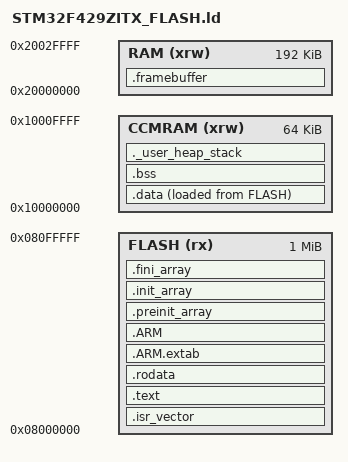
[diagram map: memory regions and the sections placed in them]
/*
******************************************************************************
**
** @file        : LinkerScript.ld
**
** @author      : Auto-generated by STM32CubeIDE
**
**  Abstract    : Linker script for STM32F429I-DISC1 Board embedding STM32F429ZITx Device from stm32f4 series
**                      2048KBytes FLASH
**                      64KBytes CCMRAM
**                      192KBytes RAM
**
**                Set heap size, stack size and stack location according
**                to application requirements.
**
**                Set memory bank area and size if external memory is used
**
**  Target      : STMicroelectronics STM32
**
**  Distribution: The file is distributed as is, without any warranty
**                of any kind.
**
******************************************************************************
** @attention
**
** Copyright (c) 2026 STMicroelectronics.
** All rights reserved.
**
** This software is licensed under terms that can be found in the LICENSE file
** in the root directory of this software component.
** If no LICENSE file comes with this software, it is provided AS-IS.
**
******************************************************************************
*/

/* Entry Point */
ENTRY(Reset_Handler)

/* Memory split, because the framebuffers live in internal SRAM now (no
   SDRAM, see display.c):

     RAM     (192K)  the two 240x320 L8 framebuffers, 150K, in .framebuffer.
                     The LTDC reads them over the bus matrix, so they have
                     to be here: the CCM is wired to the CPU only.
     CCMRAM  (64K)   everything else, .data, .bss, heap and stack. Nothing
                     in this firmware reads memory by DMA, so all of it may
                     sit where only the CPU sees it, and the CPU sees the
                     CCM without wait states.

   The startup code copies .data and clears .bss by the symbols below,
   wherever they are, and the CCM is clocked out of reset. */

/* Highest address of the user mode stack */
_estack = ORIGIN(CCMRAM) + LENGTH(CCMRAM);

_Min_Heap_Size = 0x200; /* required amount of heap */
/* Stack: the deepest user is the AI search with two 220 byte map copies,
   every function is held below 4K by -Wstack-usage in the Makefile. */
_Min_Stack_Size = 0x4000; /* required amount of stack */

/* Memories definition */
/* FLASH is capped at bank 1 (1024K of the 2048K the part has) on
   purpose: bank 2 holds the high score (sectors 14/15, hiscore_flash.c).
   An image that outgrew bank 1 fails at link time instead of being
   erased by a save. */
MEMORY
{
  CCMRAM    (xrw)    : ORIGIN = 0x10000000,   LENGTH = 64K
  RAM    (xrw)    : ORIGIN = 0x20000000,   LENGTH = 192K
  FLASH    (rx)    : ORIGIN = 0x8000000,   LENGTH = 1024K
}

/* Sections */
SECTIONS
{

  /* The startup code into "FLASH" Rom type memory */
  .isr_vector :
  {
    . = ALIGN(4);
    KEEP(*(.isr_vector)) /* Startup code */
    . = ALIGN(4);
  } >FLASH

  /* The program code and other data into "FLASH" Rom type memory */
  .text :
  {
    . = ALIGN(4);
    *(.text)           /* .text sections (code) */
    *(.text*)          /* .text* sections (code) */
    *(.glue_7)         /* glue arm to thumb code */
    *(.glue_7t)        /* glue thumb to arm code */
    *(.eh_frame)

    KEEP (*(.init))
    KEEP (*(.fini))

    . = ALIGN(4);
    _etext = .;        /* define a global symbols at end of code */
  } >FLASH

  /* Constant data into "FLASH" Rom type memory */
  .rodata :
  {
    . = ALIGN(4);
    *(.rodata)         /* .rodata sections (constants, strings, etc.) */
    *(.rodata*)        /* .rodata* sections (constants, strings, etc.) */
    . = ALIGN(4);
  } >FLASH

  .ARM.extab (READONLY) : /* The "READONLY" keyword is only supported in GCC11 and later, remove it if using GCC10 or earlier. */
  {
    . = ALIGN(4);
    *(.ARM.extab* .gnu.linkonce.armextab.*)
    . = ALIGN(4);
  } >FLASH

  .ARM (READONLY) : /* The "READONLY" keyword is only supported in GCC11 and later, remove it if using GCC10 or earlier. */
  {
    . = ALIGN(4);
    __exidx_start = .;
    *(.ARM.exidx*)
    __exidx_end = .;
    . = ALIGN(4);
  } >FLASH

  .preinit_array (READONLY) : /* The "READONLY" keyword is only supported in GCC11 and later, remove it if using GCC10 or earlier. */
  {
    . = ALIGN(4);
    PROVIDE_HIDDEN (__preinit_array_start = .);
    KEEP (*(.preinit_array*))
    PROVIDE_HIDDEN (__preinit_array_end = .);
    . = ALIGN(4);
  } >FLASH

  .init_array (READONLY) : /* The "READONLY" keyword is only supported in GCC11 and later, remove it if using GCC10 or earlier. */
  {
    . = ALIGN(4);
    PROVIDE_HIDDEN (__init_array_start = .);
    KEEP (*(SORT(.init_array.*)))
    KEEP (*(.init_array*))
    PROVIDE_HIDDEN (__init_array_end = .);
    . = ALIGN(4);
  } >FLASH

  .fini_array (READONLY) : /* The "READONLY" keyword is only supported in GCC11 and later, remove it if using GCC10 or earlier. */
  {
    . = ALIGN(4);
    PROVIDE_HIDDEN (__fini_array_start = .);
    KEEP (*(SORT(.fini_array.*)))
    KEEP (*(.fini_array*))
    PROVIDE_HIDDEN (__fini_array_end = .);
    . = ALIGN(4);
  } >FLASH

  /* Used by the startup to initialize data */
  _sidata = LOADADDR(.data);

  /* Initialized data sections into "CCMRAM" */
  .data :
  {
    . = ALIGN(4);
    _sdata = .;        /* create a global symbol at data start */
    *(.data)           /* .data sections */
    *(.data*)          /* .data* sections */
    *(.RamFunc)        /* .RamFunc sections */
    *(.RamFunc*)       /* .RamFunc* sections */

    . = ALIGN(4);
    _edata = .;        /* define a global symbol at data end */

  } >CCMRAM AT> FLASH

  /* Uninitialized data section into "CCMRAM" */
  . = ALIGN(4);
  .bss :
  {
    /* This is used by the startup in order to initialize the .bss section */
    _sbss = .;         /* define a global symbol at bss start */
    __bss_start__ = _sbss;
    *(.bss)
    *(.bss*)
    *(COMMON)

    . = ALIGN(4);
    _ebss = .;         /* define a global symbol at bss end */
    __bss_end__ = _ebss;
  } >CCMRAM

  /* User_heap_stack section, used to check that there is enough CCM left */
  ._user_heap_stack :
  {
    . = ALIGN(8);
    PROVIDE ( end = . );
    PROVIDE ( _end = . );
    . = . + _Min_Heap_Size;
    . = . + _Min_Stack_Size;
    . = ALIGN(8);
  } >CCMRAM

  /* The framebuffers, in SRAM for the LTDC. Not cleared by the startup:
     display_init() fills them before the panel shows anything. */
  .framebuffer (NOLOAD) :
  {
    . = ALIGN(4);
    *(.framebuffer)
    *(.framebuffer*)
  } >RAM

  /* Remove information from the compiler libraries */
  /DISCARD/ :
  {
    libc.a ( * )
    libm.a ( * )
    libgcc.a ( * )
  }

  .ARM.attributes 0 : { *(.ARM.attributes) }
}
